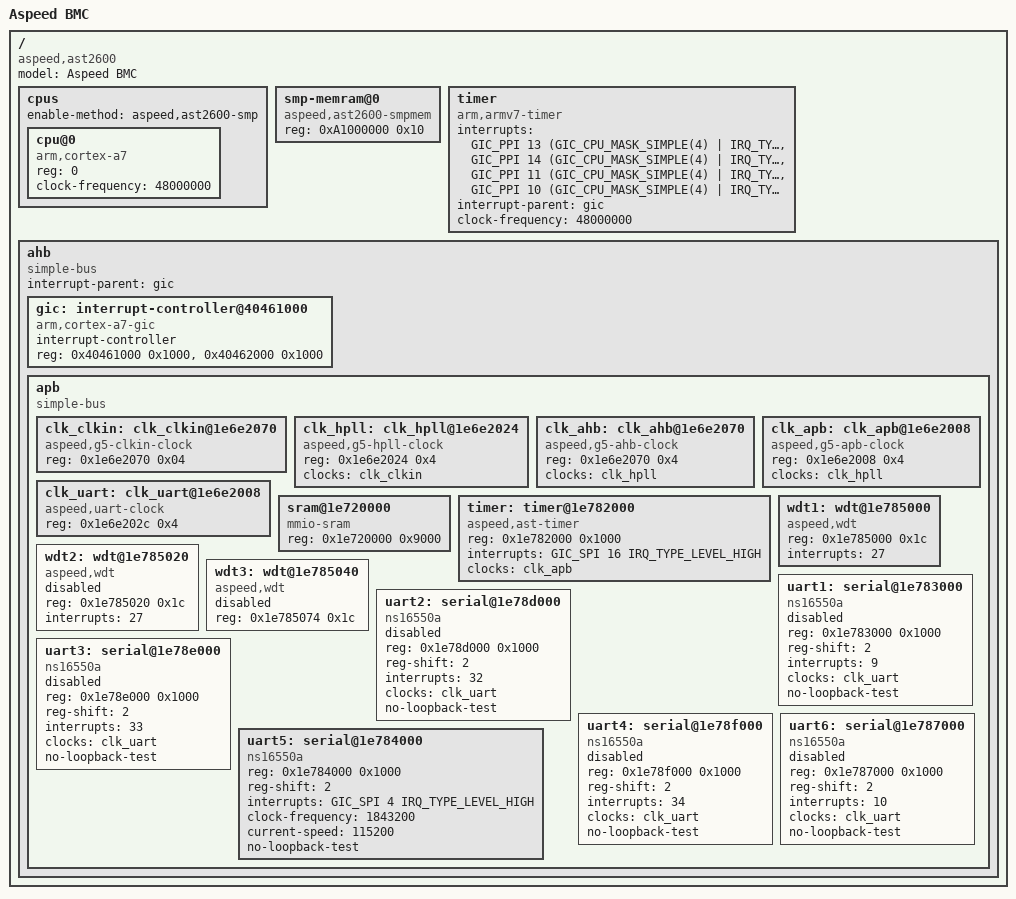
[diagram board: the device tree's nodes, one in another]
#include "skeleton.dtsi"
#include <dt-bindings/interrupt-controller/arm-gic.h>
/ {
	model = "Aspeed BMC";
	compatible = "aspeed,ast2600";
	#address-cells = <1>;
	#size-cells = <1>;
	cpus {
		#address-cells = <1>;
		#size-cells = <0>;
		enable-method = "aspeed,ast2600-smp";

		cpu@0 {
			compatible = "arm,cortex-a7";
			device_type = "cpu";
			reg = <0>;
			clock-frequency = <48000000>;
		};
	};

	smp-memram@0 {
		compatible = "aspeed,ast2600-smpmem";
		reg = <0xA1000000 0x10>;
	};

	timer {
		compatible = "arm,armv7-timer";
		interrupts = <GIC_PPI 13 (GIC_CPU_MASK_SIMPLE(4) | IRQ_TYPE_LEVEL_LOW)>,
				   <GIC_PPI 14 (GIC_CPU_MASK_SIMPLE(4) | IRQ_TYPE_LEVEL_LOW)>,
				   <GIC_PPI 11 (GIC_CPU_MASK_SIMPLE(4) | IRQ_TYPE_LEVEL_LOW)>,
				   <GIC_PPI 10 (GIC_CPU_MASK_SIMPLE(4) | IRQ_TYPE_LEVEL_LOW)>;
		interrupt-parent = <&gic>;
		clock-frequency = <48000000>;

        };


	ahb {
		compatible = "simple-bus";
		#address-cells = <1>;
		#size-cells = <1>;
		interrupt-parent = <&gic>;
		ranges;

		gic: interrupt-controller@40461000{
			compatible = "arm,cortex-a7-gic";
			#interrupt-cells = <3>;
			#address-cells = <1>;
			#size-cells = <1>;
			interrupt-controller;
			reg = <0x40461000 0x1000>,
			      <0x40462000 0x1000>;
		};
		apb {
			compatible = "simple-bus";
			#address-cells = <1>;
			#size-cells = <1>;
			ranges;

			clk_clkin: clk_clkin@1e6e2070 {
				#clock-cells = <0>;
				compatible = "aspeed,g5-clkin-clock";
				reg = <0x1e6e2070 0x04>;
			};

			clk_hpll: clk_hpll@1e6e2024 {
				#clock-cells = <0>;
				compatible = "aspeed,g5-hpll-clock";
				reg = <0x1e6e2024 0x4>;
				clocks = <&clk_clkin>;
			};

			clk_ahb: clk_ahb@1e6e2070 {
				#clock-cells = <0>;
				compatible = "aspeed,g5-ahb-clock";
				reg = <0x1e6e2070 0x4>;
				clocks = <&clk_hpll>;
			};

			clk_apb: clk_apb@1e6e2008 {
				#clock-cells = <0>;
				compatible = "aspeed,g5-apb-clock";
				reg = <0x1e6e2008 0x4>;
				clocks = <&clk_hpll>;
			};

			clk_uart: clk_uart@1e6e2008 {
				#clock-cells = <0>;
				compatible = "aspeed,uart-clock";
				reg = <0x1e6e202c 0x4>;
			};

			sram@1e720000 {
				compatible = "mmio-sram";
				reg = <0x1e720000 0x9000>;	// 36K
			};

			timer: timer@1e782000 {
				compatible = "aspeed,ast-timer";
				reg = <0x1e782000 0x1000>;
				// The moxart_timer driver registers only one
				// interrupt and assumes it's for timer 1
				//interrupts = <16 17 18 35 36 37 38 39>;
				//interrupts = <48>;
				interrupts = <GIC_SPI 16 IRQ_TYPE_LEVEL_HIGH>;
				clocks = <&clk_apb>;
			};

			wdt1: wdt@1e785000 {
				compatible = "aspeed,wdt";
				reg = <0x1e785000 0x1c>;
				interrupts = <27>;
			};

			wdt2: wdt@1e785020 {
				compatible = "aspeed,wdt";
				reg = <0x1e785020 0x1c>;
				interrupts = <27>;
				status = "disabled";
			};

			wdt3: wdt@1e785040 {
				compatible = "aspeed,wdt";
				reg = <0x1e785074 0x1c>;
				status = "disabled";
			};

			uart1: serial@1e783000 {
				compatible = "ns16550a";
				reg = <0x1e783000 0x1000>;
				reg-shift = <2>;
				interrupts = <9>;
				clocks = <&clk_uart>;
				no-loopback-test;
				status = "disabled";
			};

			uart2: serial@1e78d000 {
				compatible = "ns16550a";
				reg = <0x1e78d000 0x1000>;
				reg-shift = <2>;
				interrupts = <32>;
				clocks = <&clk_uart>;
				no-loopback-test;
				status = "disabled";
			};

			uart3: serial@1e78e000 {
				compatible = "ns16550a";
				reg = <0x1e78e000 0x1000>;
				reg-shift = <2>;
				interrupts = <33>;
				clocks = <&clk_uart>;
				no-loopback-test;
				status = "disabled";
			};

			uart4: serial@1e78f000 {
				compatible = "ns16550a";
				reg = <0x1e78f000 0x1000>;
				reg-shift = <2>;
				interrupts = <34>;
				clocks = <&clk_uart>;
				no-loopback-test;
				status = "disabled";
			};

			uart5: serial@1e784000 {
				compatible = "ns16550a";
				reg = <0x1e784000 0x1000>;
				reg-shift = <2>;
				interrupts = <GIC_SPI 4 IRQ_TYPE_LEVEL_HIGH>;
				clock-frequency = <1843200>;
				current-speed = <115200>;
				no-loopback-test;
				status = "okay";
			};

			uart6: serial@1e787000 {
				compatible = "ns16550a";
				reg = <0x1e787000 0x1000>;
				reg-shift = <2>;
				interrupts = <10>;
				clocks = <&clk_uart>;
				no-loopback-test;
				status = "disabled";
			};
		};
	};
};
